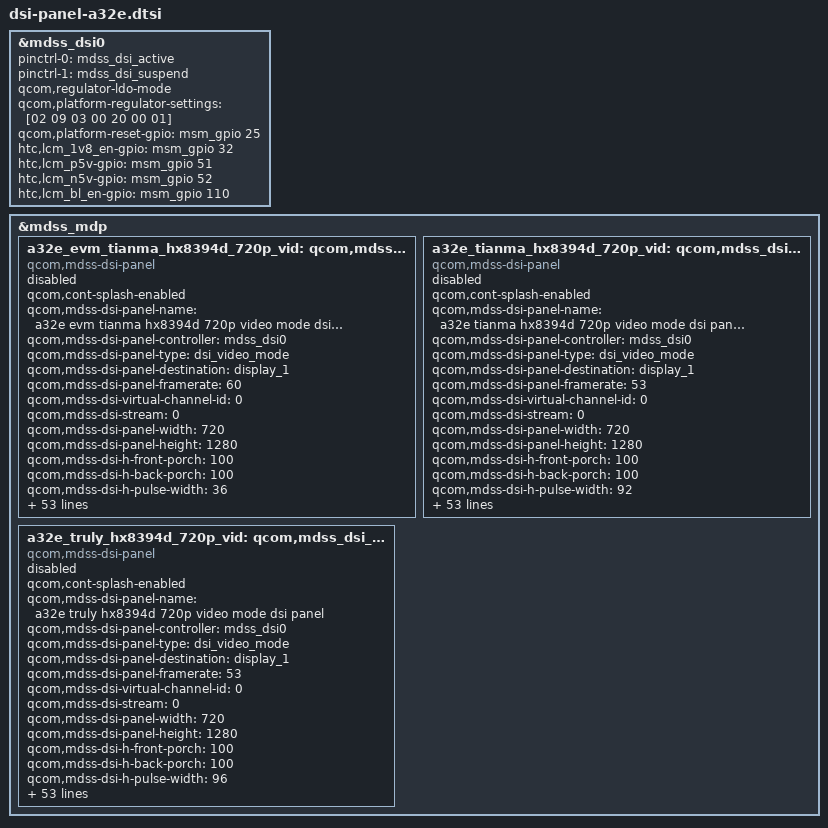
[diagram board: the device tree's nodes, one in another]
&mdss_dsi0 {
	pinctrl-names = "mdss_default", "mdss_sleep";
	pinctrl-0 = <&mdss_dsi_active>;
	pinctrl-1 = <&mdss_dsi_suspend>;

	/* L2: MIPI power 1.2V
	   L6: MIPI DSI PLL power 1.8V
	   Above power are enabled when PM8909 is ON */
	qcom,regulator-ldo-mode;
	qcom,platform-regulator-settings = [02 09 03 00 20 00 01];

	qcom,platform-reset-gpio = <&msm_gpio 25 0>;
	htc,lcm_1v8_en-gpio = <&msm_gpio 32 0>;
	htc,lcm_p5v-gpio = <&msm_gpio 51 0>;
	htc,lcm_n5v-gpio = <&msm_gpio 52 0>;
	htc,lcm_bl_en-gpio = <&msm_gpio 110 0>;
};

&mdss_mdp {
	a32e_evm_tianma_hx8394d_720p_vid:qcom,mdss_dsi_a32e_evm_tianma_hx8394d_720p_video {
		compatible = "qcom,mdss-dsi-panel";
		status = "disable";
		qcom,cont-splash-enabled;
		qcom,mdss-dsi-panel-name = "a32e evm tianma hx8394d 720p video mode dsi panel";
		qcom,mdss-dsi-panel-controller = <&mdss_dsi0>;
		qcom,mdss-dsi-panel-type = "dsi_video_mode";
		qcom,mdss-dsi-panel-destination = "display_1";
		qcom,mdss-dsi-panel-framerate = <60>;
		qcom,mdss-dsi-virtual-channel-id = <0>;
		qcom,mdss-dsi-stream = <0>;
		qcom,mdss-dsi-panel-width = <720>;
		qcom,mdss-dsi-panel-height = <1280>;
		qcom,mdss-dsi-h-front-porch = <100>;
		qcom,mdss-dsi-h-back-porch = <100>;
		qcom,mdss-dsi-h-pulse-width = <36>;
		qcom,mdss-dsi-h-sync-skew = <0>;
		qcom,mdss-dsi-v-back-porch = <12>;
		qcom,mdss-dsi-v-front-porch = <15>;
		qcom,mdss-dsi-v-pulse-width = <4>;
		qcom,mdss-dsi-h-left-border = <0>;
		qcom,mdss-dsi-h-right-border = <0>;
		qcom,mdss-dsi-v-top-border = <0>;
		qcom,mdss-dsi-v-bottom-border = <0>;
		qcom,mdss-dsi-bpp = <24>;
		qcom,mdss-dsi-color-order = "rgb_swap_rgb";
		qcom,mdss-dsi-underflow-color = <0>;
		qcom,mdss-dsi-border-color = <0>;
		qcom,mdss-dsi-on-command = [
			39 00 00 00 00 00 04 B9 FF 83 94
			39 00 00 00 00 00 03 BA 72 83
			39 00 00 00 00 00 10 B1 6C 0F 0F 35 04 11 F1 80 DE D4 23 80 C0 D2 18
			39 00 00 00 00 00 0C B2 00 64 0E 0D 32 23 08 08 1C 4D 00
			15 00 00 00 01 00 02 BC 07
			39 00 00 00 00 00 0D B4 00 FF 03 5A 03 5A 03 5A 01 6A 01 6A
			39 00 00 00 00 00 26 D3 00 07 00 00 00 10 00 32 10 05 00 05 32 10 00 00 00 32 10 00 00 00 36 03 09 09 37 00 00 37 00 00 00 00 0A 00 01
			39 00 00 00 00 00 2D D5 02 03 00 01 06 07 04 05 20 21 22 23 18 18 18 18 18 18 18 18 18 18 18 18 18 18 18 18 18 18 18 18 18 18 18 18 18 18 24 25 18 18 19 19
			39 00 00 00 00 00 2D D6 05 04 07 06 01 00 03 02 23 22 21 20 18 18 18 18 18 18 18 18 18 18 18 18 18 18 18 18 18 18 18 18 18 18 18 18 18 18 25 24 19 19 18 18
			39 00 00 00 00 00 2B E0 00 11 16 2f 35 3f 25 3e 08 0b 0d 17 0e 12 14 13 14 07 10 11 18 00 10 17 30 35 3f 24 3e 07 0c 0d 19 0f 12 15 12 14 06 10 10 16
			39 00 00 00 00 00 02 BD 00
			39 00 00 00 00 00 2C C1 01 00 08 0E 14 1D 25 2E 36 3F 47 4F 58 60 68 70 79 81 89 91 9A A1 A8 B1 B8 C0 C9 D0 D8 E0 E8 EF F7 FF 03 B2 98 98 29 72 0F 0A C0
			39 00 00 00 00 00 02 BD 01
			39 00 00 00 00 00 2B C1 00 08 0D 14 1D 26 2E 37 40 48 50 59 61 69 71 7A 82 8A 93 9B A2 AA B2 B9 C2 CB D2 DA E1 E9 F0 F7 FE 0F 88 08 AD 73 DF 0D 4A 00
			39 00 00 00 00 00 02 BD 02
			39 00 00 00 00 00 2B C1 00 04 08 12 1B 24 2C 33 3C 44 4C 54 5C 64 6B 73 7B 83 8B 93 9B A2 A9 B0 B8 BF C7 CE D6 DC E3 E9 EE 08 03 E6 CF F6 4B 22 20 00
			15 00 00 00 00 00 02 CC 09
			39 00 00 00 00 00 03 C0 30 14
			39 00 00 00 00 00 05 C7 00 C0 40 C0
			15 00 00 00 00 00 02 51 FF
			39 00 00 00 00 00 08 C9 1F 00 14 1E 81 1E 00
			15 00 00 00 05 00 02 55 11
			15 00 00 00 00 00 02 5E 00
			39 00 00 00 00 00 0A CA 2D 26 25 23 22 22 21 20 20
			39 00 00 00 00 00 23 CE 00 00 00 00 00 00 00 00 00 00 00 00 00 00 00 00 00 00 00 00 00 00 00 00 00 00 00 00 00 00 00 00 00 00
			15 00 00 00 00 00 02 53 24
			39 00 00 00 0A 00 03 E4 05 00
			39 00 00 00 00 00 20 E5 00 00 07 05 06 00 00 00 00 00 00 01 01 01 01 02 F6 08 00 08 06 05 04 06 04 04 06 06 05 03 02
			39 00 00 00 05 00 14 E6 00 08 00 05 05 3F 20 7F 20 7F 20 10 10 10 20 20 20 00 00
			15 01 00 00 78 00 02 11 00
			05 01 00 00 28 00 02 29 00
		];
		qcom,mdss-dsi-off-command = [
			05 01 00 00 01 00 02 28 00
			05 01 00 00 78 00 02 10 00
		];
		qcom,mdss-dsi-on-command-state = "dsi_lp_mode";
		qcom,mdss-dsi-off-command-state = "dsi_hs_mode";
		qcom,mdss-dsi-h-sync-pulse = <0>;
		qcom,mdss-dsi-traffic-mode = "non_burst_sync_event";
		qcom,mdss-dsi-bllp-eof-power-mode;
		qcom,mdss-dsi-lane-map = "lane_map_0123";
		qcom,mdss-dsi-bllp-power-mode;
		qcom,mdss-dsi-lane-0-state;
		qcom,mdss-dsi-lane-1-state;
		qcom,mdss-dsi-lane-2-state;
		qcom,mdss-dsi-panel-timings = [38 2F 25 00 43 3D 2A 31 3C 03 04 00];
		qcom,mdss-dsi-t-clk-post = <0x1f>;
		qcom,mdss-dsi-t-clk-pre = <0x39>;
		qcom,mdss-dsi-bl-min-level = <30>;
		qcom,mdss-dsi-bl-max-level = <255>;
		qcom,mdss-dsi-dma-trigger = "trigger_sw";
		qcom,mdss-dsi-mdp-trigger = "none";
		qcom,mdss-dsi-bl-pmic-control-type = "bl_ctrl_i2c";
		qcom,mdss-dsi-default-command-state = "dsi_hs_mode";
		htc,cabc-off-cmds = [15 00 00 00 05 00 02 55 00];
		htc,cabc-ui-cmds = [
			15 00 00 00 05 00 02 55 11
			15 00 00 00 05 00 02 5E 00
			39 00 00 00 00 00 0A CA 2D 26 25 23 22 22 21 20 20
			39 00 00 00 00 00 23 CE 00 00 00 00 00 00 00 00 00 00 00 00 00 00 00 00 00 00 00 00 00 00 00 00 00 00 00 00 00 00 00 00 00 00
		];
		htc,cabc-video-cmds = [
			15 00 00 00 05 00 02 55 11
			15 00 00 00 05 00 02 5E 00
			39 00 00 00 00 00 0A CA 40 2E 2A 24 23 22 21 20 20
			39 00 00 00 00 00 23 CE 00 00 00 00 00 00 00 00 00 00 00 00 00 00 00 00 00 00 00 00 00 00 00 00 00 00 00 00 00 00 00 00 00 00
		];
		htc,dimming-on-cmds = [15 01 00 00 00 00 02 53 2C];
		qcom,mdss-pan-physical-width-dimension = <68>;
		qcom,mdss-pan-physical-height-dimension = <121>;
		qcom,mdss-shrink-pwm = <6 76 255>;
		qcom,mdss-dsi-lp11-init;
		htc,mdss-camera-blk = <194>;
		htc,panel-id = <1>;
	};

	a32e_tianma_hx8394d_720p_vid:qcom,mdss_dsi_a32e_tianma_hx8394d_720p_video {
		compatible = "qcom,mdss-dsi-panel";
		status = "disable";
		qcom,cont-splash-enabled;
		qcom,mdss-dsi-panel-name = "a32e tianma hx8394d 720p video mode dsi panel";
		qcom,mdss-dsi-panel-controller = <&mdss_dsi0>;
		qcom,mdss-dsi-panel-type = "dsi_video_mode";
		qcom,mdss-dsi-panel-destination = "display_1";
		qcom,mdss-dsi-panel-framerate = <53>;
		qcom,mdss-dsi-virtual-channel-id = <0>;
		qcom,mdss-dsi-stream = <0>;
		qcom,mdss-dsi-panel-width = <720>;
		qcom,mdss-dsi-panel-height = <1280>;
		qcom,mdss-dsi-h-front-porch = <100>;
		qcom,mdss-dsi-h-back-porch = <100>;
		qcom,mdss-dsi-h-pulse-width = <92>;
		qcom,mdss-dsi-h-sync-skew = <0>;
		qcom,mdss-dsi-v-back-porch = <12>;
		qcom,mdss-dsi-v-front-porch = <16>;
		qcom,mdss-dsi-v-pulse-width = <4>;
		qcom,mdss-dsi-h-left-border = <0>;
		qcom,mdss-dsi-h-right-border = <0>;
		qcom,mdss-dsi-v-top-border = <0>;
		qcom,mdss-dsi-v-bottom-border = <0>;
		qcom,mdss-dsi-bpp = <24>;
		qcom,mdss-dsi-color-order = "rgb_swap_rgb";
		qcom,mdss-dsi-underflow-color = <0>;
		qcom,mdss-dsi-border-color = <0>;
		qcom,mdss-dsi-on-command = [
			39 01 00 00 00 00 04 B9 FF 83 94 /* Set EXTC */
			39 01 00 00 00 00 03 BA 72 83 /* Set MIPI */
			39 01 00 00 00 00 10 B1 6C 0F 0F 35 04 11 F1 80 DE D4 23 80 C0 D2 18 /* Set Power */
			39 01 00 00 00 00 0C B2 00 64 0E 0D 32 23 08 08 1C 4D 00 /* Set Display: column inversion */
			15 01 00 00 01 00 02 BC 07 /* set VDDD */
			39 01 00 00 00 00 0D B4 00 FF 03 5A 03 5A 03 5A 01 6A 01 6A /* Set CYC(panel driving timing): column inversion */
			39 01 00 00 00 00 26 D3 00 07 00 00 00 10 00 32 10 05 00 05 32 10 00 00 00 32 10 00 00 00 36 03 09 09 37 00 00 37 00 00 00 00 0A 00 01 /* Set GIP option 0: column inversion */
			39 01 00 00 00 00 2D D5 02 03 00 01 06 07 04 05 20 21 22 23 18 18 18 18 18 18 18 18 18 18 18 18 18 18 18 18 18 18 18 18 18 18 18 18 18 18 24 25 18 18 19 19 /* Set GIP option 1 */
			39 01 00 00 00 00 2D D6 05 04 07 06 01 00 03 02 23 22 21 20 18 18 18 18 18 18 18 18 18 18 18 18 18 18 18 18 18 18 18 18 18 18 18 18 18 18 25 24 19 19 18 18 /* Set GIP option 2 */
			39 01 00 00 00 00 2B E0 02 0E 16 29 28 3F 27 45 06 0A 0C 17 10 14 16 14 15 08 12 16 19 02 0E 16 29 28 3F 27 45 06 0A 0C 17 10 14 16 14 15 08 12 16 19 /* Set Gamma */
			15 01 00 00 00 00 02 BD 00 /* Set DGC page 0 */
			39 01 00 00 00 00 2C C1 01 00 08 0E 14 1D 25 2E 36 3F 47 4F 58 60 68 70 79 81 89 91 9A A1 A8 B1 B8 C0 C9 D0 D8 E0 E8 EF F7 FF 03 B2 98 98 29 72 0F 0A C0 /* Set DGC R */
			15 01 00 00 00 00 02 BD 01 /* Set DGC page 1 */
			39 01 00 00 00 00 2B C1 00 08 0D 14 1D 26 2E 37 40 48 50 59 61 69 71 7A 82 8A 93 9B A2 AA B2 B9 C2 CB D2 DA E1 E9 F0 F7 FE 0F 88 08 AD 73 DF 0D 4A 00 /* Set DGC G */
			15 01 00 00 00 00 02 BD 02 /* Set DGC page 2 */
			39 01 00 00 00 00 2B C1 00 08 0B 14 1D 26 2F 37 40 48 51 5A 62 6B 72 7B 83 8C 94 9D A4 AB B4 BB C3 CC D4 DA E1 E8 EF F5 FA 08 03 E6 CF F6 B4 22 20 00 /* Set DGC B */
			15 01 00 00 00 00 02 CC 09 /* Set Panel */
			39 01 00 00 00 00 03 C0 30 14 /* Set Source Option:Column inversion */
			39 01 00 00 00 00 05 C7 00 C0 40 C0 /* Set TCON option: Column inversion */
			15 01 00 00 05 00 02 51 FF /* Set display brightness */
			15 01 00 00 05 00 02 53 24 /* Set CTRL display PWM out */
			39 01 00 00 00 00 08 C9 1F 00 14 1E 81 1E 00 /* Set CABC control */
			15 01 00 00 05 00 02 55 01 /* Set CABC mode */
			15 01 00 00 05 00 02 5E 00 /* Set CABC minimum brightness */
			39 01 00 00 00 00 0A CA 2D 26 25 22 21 21 20 20 20 /* SET CABC GAIN: still mode (70~100%) */
			/* 39 01 00 00 00 00 0A CA 40 2E 2A 23 22 21 20 20 20 */ /* SET CABC GAIN: movie mode (50~100%) */
			39 01 00 00 00 00 23 CE 00 00 00 00 00 00 00 00 00 00 00 00 00 00 00 00 00 00 00 00 00 00 00 00 00 00 00 00 00 00 00 00 00 00 /* SET CABC LUT: Still mode (70~100%) */
			39 01 00 00 0A 00 03 E4 DB 00 /* SET CE MODE */
			39 01 00 00 00 00 2C E5 00 08 0E 0A 09 00 20 20 20 10 00 00 00 00 00 00 80 0A 20 08 09 0A 0E 0B 0B 0A 0A 09 08 05 03 00 00 00 00 00 00 00 00 00 00 00 00 /* SET CE */
			39 01 00 00 05 00 12 E6 00 00 00 05 05 1C 18 1C 20 20 20 16 12 16 1C 20 20 /* SET CE SEL */
			15 01 00 00 78 00 02 11 00 /* Sleep Out */
			05 01 00 00 0A 00 02 29 00 /* Display On */
		];
		qcom,mdss-dsi-off-command = [
			05 01 00 00 0A 00 02 28 00 /* Display Off */
			05 01 00 00 28 00 02 10 00 /* Sleep In */
		];
		qcom,mdss-dsi-on-command-state = "dsi_lp_mode";
		qcom,mdss-dsi-off-command-state = "dsi_hs_mode";
		qcom,mdss-dsi-h-sync-pulse = <0>;
		qcom,mdss-dsi-traffic-mode = "non_burst_sync_event";
		qcom,mdss-dsi-bllp-eof-power-mode;
		qcom,mdss-dsi-lane-map = "lane_map_0123";
		qcom,mdss-dsi-bllp-power-mode;
		qcom,mdss-dsi-lane-0-state;
		qcom,mdss-dsi-lane-1-state;
		qcom,mdss-dsi-lane-2-state;
		/* from QCT excel */
		/* qcom,mdss-dsi-panel-timings = [33 22 18 00 4A 4E 1C 26 1D 03 04 00];
		qcom,mdss-dsi-t-clk-post = <0x04>;
		qcom,mdss-dsi-t-clk-pre = <0x13>; */
		/* from A51 panel */
		qcom,mdss-dsi-panel-timings = [38 2F 25 00 43 3D 2A 31 3C 03 04 00];
		qcom,mdss-dsi-t-clk-post = <0x1f>;
		qcom,mdss-dsi-t-clk-pre = <0x39>;
		qcom,mdss-dsi-bl-min-level = <30>;
		qcom,mdss-dsi-bl-max-level = <255>;
		qcom,mdss-dsi-dma-trigger = "trigger_sw";
		qcom,mdss-dsi-mdp-trigger = "none";
		qcom,mdss-dsi-bl-pmic-control-type = "bl_ctrl_i2c";
		qcom,mdss-dsi-default-command-state = "dsi_hs_mode";
		htc,cabc-off-cmds = [15 01 00 00 05 00 02 55 00];
		htc,cabc-ui-cmds = [
			15 01 00 00 05 00 02 55 01
			15 01 00 00 05 00 02 5E 00
			39 01 00 00 00 00 0A CA 2D 26 25 22 21 21 20 20 20
			39 01 00 00 00 00 23 CE 00 00 00 00 00 00 00 00 00 00 00 00 00 00 00 00 00 00 00 00 00 00 00 00 00 00 00 00 00 00 00 00 00 00
		];
		htc,cabc-video-cmds = [
			15 01 00 00 05 00 02 55 01
			15 01 00 00 05 00 02 5E 00
			39 01 00 00 00 00 0A CA 40 2E 2A 23 22 21 20 20 20
			39 01 00 00 00 00 23 CE 00 00 00 00 00 00 00 00 00 00 00 00 00 00 00 00 00 00 00 00 00 00 00 00 00 00 00 00 00 00 00 00 00 00
		];
		htc,dimming-on-cmds = [15 01 00 00 00 00 02 53 2C];
		qcom,mdss-pan-physical-width-dimension = <62>;
		qcom,mdss-pan-physical-height-dimension = <110>;
		qcom,mdss-shrink-pwm = <6 76 255>;
		qcom,mdss-dsi-lp11-init;
		htc,mdss-camera-blk = <194>;
		htc,panel-id = <2>;
	};

	a32e_truly_hx8394d_720p_vid:qcom,mdss_dsi_a32e_truly_hx8394d_720p_video {
		compatible = "qcom,mdss-dsi-panel";
		status = "disable";
		qcom,cont-splash-enabled;
		qcom,mdss-dsi-panel-name = "a32e truly hx8394d 720p video mode dsi panel";
		qcom,mdss-dsi-panel-controller = <&mdss_dsi0>;
		qcom,mdss-dsi-panel-type = "dsi_video_mode";
		qcom,mdss-dsi-panel-destination = "display_1";
		qcom,mdss-dsi-panel-framerate = <53>;
		qcom,mdss-dsi-virtual-channel-id = <0>;
		qcom,mdss-dsi-stream = <0>;
		qcom,mdss-dsi-panel-width = <720>;
		qcom,mdss-dsi-panel-height = <1280>;
		/* the same porch setting as Tianma panel */
		qcom,mdss-dsi-h-front-porch = <100>;
		qcom,mdss-dsi-h-back-porch = <100>;
		qcom,mdss-dsi-h-pulse-width = <96>;
		qcom,mdss-dsi-h-sync-skew = <0>;
		qcom,mdss-dsi-v-back-porch = <16>;
		qcom,mdss-dsi-v-front-porch = <9>;
		qcom,mdss-dsi-v-pulse-width = <2>;
		qcom,mdss-dsi-h-left-border = <0>;
		qcom,mdss-dsi-h-right-border = <0>;
		qcom,mdss-dsi-v-top-border = <0>;
		qcom,mdss-dsi-v-bottom-border = <0>;
		qcom,mdss-dsi-bpp = <24>;
		qcom,mdss-dsi-color-order = "rgb_swap_rgb";
		qcom,mdss-dsi-underflow-color = <0>;
		qcom,mdss-dsi-border-color = <0>;
		qcom,mdss-dsi-on-command = [
			39 01 00 00 00 00 04 B9 FF 83 94 /* Set EXTC */
			39 01 00 00 00 00 03 BA 72 83 /* Set MIPI */
			39 01 00 00 00 00 10 B1 6A 55 15 15 15 11 F1 80 E8 95 23 80 C0 D2 58 /* Set Power: VGH=15, VGL=-10.2 */
			39 01 00 00 00 00 0C B2 00 64 10 07 22 1C 08 08 1C 4D 00 /* Set Display: column inversion */
			15 01 00 00 00 00 02 BC 07 /* set VDDD */
			39 01 00 00 00 00 0D B4 00 FF 03 5C 03 5C 03 5C 01 70 11 70 /* Set CYC(panel driving timing): column inversion */
			39 01 00 00 00 00 02 D2 55
			39 01 00 00 00 00 1F D3 00 06 00 01 1A 08 00 32 10 07 00 07 54 15 0F 05 04 02 12 10 05 07 33 33 0B 0B 37 10 07 07 /* Set GIP option 0: column inversion */
			39 01 00 00 00 00 2D D5 19 19 18 18 1B 1B 1A 1A 04 05 06 07 00 01 02 03 20 21 18 18 22 23 18 18 18 18 18 18 18 18 18 18 18 18 18 18 18 18 18 18 18 18 18 18 /* Set GIP option 1 */
			39 01 00 00 00 00 2D D6 18 18 19 19 1B 1B 1A 1A 03 02 01 00 07 06 05 04 23 22 18 18 21 20 18 18 18 18 18 18 18 18 18 18 18 18 18 18 18 18 18 18 18 18 18 18 /* Set GIP option 2 */
			39 01 00 00 00 00 2B E0 00 03 09 23 27 3F 1C 3A 06 0A 0B 17 0D 10 12 11 13 07 11 14 18 00 03 09 23 29 3F 1C 3A 06 0A 0B 17 0E 11 12 11 13 07 12 13 18 /* Set Gamma */
			39 01 00 00 00 00 03 C0 30 14 /* Set Source Option:Column inversion */
			39 01 00 00 00 00 05 C7 00 C0 40 C0 /* Set TCON option: Column inversion */
			15 01 00 00 00 00 02 CC 09 /* Set Panel */
			39 01 00 00 00 00 02 DF 87
			15 01 00 00 05 00 02 51 FF /* Set display brightness */
			15 01 00 00 05 00 02 53 24 /* Set CTRL display PWM out */
			39 01 00 00 00 00 08 C9 1F 00 14 1E 81 1E 00 /* Set CABC control */
			15 01 00 00 05 00 02 55 01 /* Set CABC mode */
			15 01 00 00 05 00 02 5E 00 /* Set CABC minimum brightness */
			39 01 00 00 00 00 0A CA 2D 26 25 22 21 21 20 20 20 /* SET CABC GAIN: still mode (70~100%) */
			39 01 00 00 00 00 23 CE 00 00 00 00 00 00 00 00 00 00 00 00 00 00 00 00 00 00 00 00 00 00 00 00 00 00 00 00 00 00 00 00 00 00 /* SET CABC LUT: Still mode (70~100%) */
			39 01 00 00 0A 00 03 E4 DB 00 /* SET CE MODE */
			39 01 00 00 00 00 2C E5 00 08 0E 0A 09 00 20 20 20 10 00 00 00 00 00 00 80 0A 20 08 09 0A 0E 0B 0B 0A 0A 09 08 05 03 00 00 00 00 00 00 00 00 00 00 00 00 /* SET CE */
			39 01 00 00 05 00 12 E6 00 00 00 05 05 1C 18 1C 20 20 20 16 12 16 1C 20 20 /* SET CE SEL */
			15 01 00 00 78 00 02 11 00 /* Sleep Out */
			05 01 00 00 0A 00 02 29 00 /* Display On */
		];
		qcom,mdss-dsi-off-command = [
			05 01 00 00 0A 00 02 28 00 /* Display Off */
			05 01 00 00 28 00 02 10 00 /* Sleep In */
		];
		qcom,mdss-dsi-on-command-state = "dsi_lp_mode";
		qcom,mdss-dsi-off-command-state = "dsi_hs_mode";
		qcom,mdss-dsi-h-sync-pulse = <0>;
		qcom,mdss-dsi-traffic-mode = "non_burst_sync_event";
		qcom,mdss-dsi-bllp-eof-power-mode;
		qcom,mdss-dsi-lane-map = "lane_map_0123";
		qcom,mdss-dsi-bllp-power-mode;
		qcom,mdss-dsi-lane-0-state;
		qcom,mdss-dsi-lane-1-state;
		qcom,mdss-dsi-lane-2-state;
		/* the same timing setting as Tianma panel */
		qcom,mdss-dsi-panel-timings = [38 2F 25 00 43 3D 2A 31 3C 03 04 00];
		qcom,mdss-dsi-t-clk-post = <0x1F>;
		qcom,mdss-dsi-t-clk-pre = <0x39>;
		qcom,mdss-dsi-bl-min-level = <30>;
		qcom,mdss-dsi-bl-max-level = <255>;
		qcom,mdss-dsi-dma-trigger = "trigger_sw";
		qcom,mdss-dsi-mdp-trigger = "none";
		qcom,mdss-dsi-bl-pmic-control-type = "bl_ctrl_i2c";
		qcom,mdss-dsi-default-command-state = "dsi_hs_mode";
		htc,cabc-off-cmds = [15 01 00 00 05 00 02 55 00];
		htc,cabc-ui-cmds = [
			15 01 00 00 05 00 02 55 01
			15 01 00 00 05 00 02 5E 00
			39 01 00 00 00 00 0A CA 2D 26 25 22 21 21 20 20 20
			39 01 00 00 00 00 23 CE 00 00 00 00 00 00 00 00 00 00 00 00 00 00 00 00 00 00 00 00 00 00 00 00 00 00 00 00 00 00 00 00 00 00
		];
		htc,cabc-video-cmds = [
			15 01 00 00 05 00 02 55 01
			15 01 00 00 05 00 02 5E 00
			39 01 00 00 00 00 0A CA 40 2E 2A 23 22 21 20 20 20
			39 01 00 00 00 00 23 CE 00 00 00 00 00 00 00 00 00 00 00 00 00 00 00 00 00 00 00 00 00 00 00 00 00 00 00 00 00 00 00 00 00 00
		];
		htc,dimming-on-cmds = [15 01 00 00 00 00 02 53 2C];
		qcom,mdss-pan-physical-width-dimension = <62>;
		qcom,mdss-pan-physical-height-dimension = <110>;
		qcom,mdss-shrink-pwm = <6 76 255>;
		qcom,mdss-dsi-lp11-init;
		htc,mdss-camera-blk = <194>;
		htc,panel-id = <3>;
	};
};
